# ESP32-H2 register map
Vendor: ESPRESSIF SYSTEMS (SHANGHAI) CO., LTD.; Series: ESP32 H-Series; File version: 12
CPU: RV32IMAC r0p0, little endian, no MPU, no FPU, 0 interrupt priority bits
Address unit: 32 bits
Registers are 32-bit, read-write, reset 0x0 unless marked. A register's access mark holds for its fields unless they carry their own. Offsets are from the block's base; [hi:lo] are bit positions; {n}, {i} and the like mark numbered series.

## MCPWM0 — Motor Control Pulse-Width Modulation 0
Base 0x60014000
0x00 CLK_CFG — PWM clock prescaler register.
  [7:0] CLK_PRESCALE — Period of PWM_clk = 6.25ns * (PWM_CLK_PRESCALE + 1)
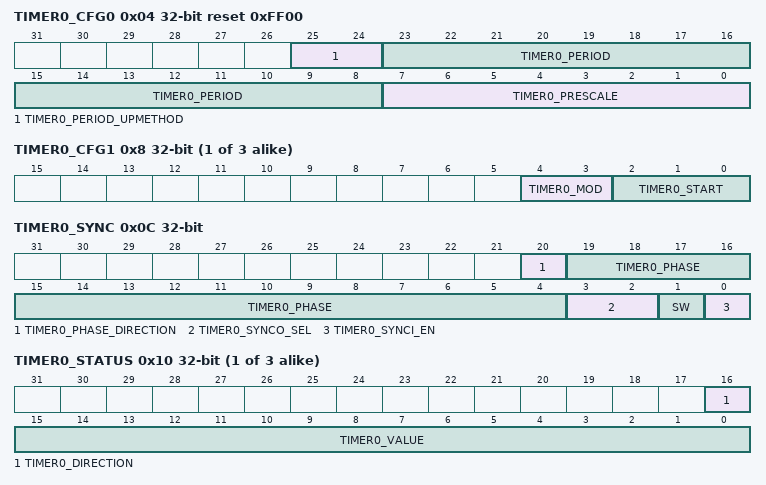
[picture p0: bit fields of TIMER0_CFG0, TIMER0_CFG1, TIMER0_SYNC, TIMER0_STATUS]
0x04 TIMER0_CFG0 reset 0xFF00 — PWM timer0 period and update method configuration register.
  [25:24] TIMER0_PERIOD_UPMETHOD — Update method for active register of PWM timer0 period, 0: immediate, 1: TEZ, 2: sync, 3: TEZ | sync. TEZ here and below means timer equal zero event
  [23:8] TIMER0_PERIOD — period shadow register of PWM timer0
  [7:0] TIMER0_PRESCALE — period of PT0_clk = Period of PWM_clk * (PWM_TIMER0_PRESCALE + 1)
{0x8+0x10*i} TIMER{i}_CFG1 (i=0..2) — PWM timer{i} working mode and start/stop control configuration register.
  [4:3] TIMER{i}_MOD — PWM timer{i} working mode, 0: freeze, 1: increase mode, 2: decrease mode, 3: up-down mode
  [2:0] TIMER{i}_START — PWM timer{i} start and stop control. 0: if PWM timer{i} starts, then stops at TEZ, 1: if timer{i} starts, then stops at TEP, 2: PWM timer{i} starts and runs on, 3: timer{i} starts and stops at the next TEZ, 4: timer{i} starts and stops at the next TEP. TEP here and below means the event that happens when the timer equals to period
0x0C TIMER0_SYNC — PWM timer0 sync function configuration register.
  [20] TIMER0_PHASE_DIRECTION — Configure the PWM timer0's direction when timer0 mode is up-down mode: 0-increase,1-decrease
  [19:4] TIMER0_PHASE — phase for timer reload on sync event
  [3:2] TIMER0_SYNCO_SEL — PWM timer0 sync_out selection, 0: sync_in, 1: TEZ, 2: TEP, and sync out will always generate when toggling the reg_timer0_sync_sw bit
  [1] SW — Toggling this bit will trigger a software sync.
  [0] TIMER0_SYNCI_EN — When set, timer reloading with phase on sync input event is enabled.
{0x10+0x10*i} TIMER{i}_STATUS ro (i=0..2) — PWM timer{i} status register.
  [16] TIMER{i}_DIRECTION — current PWM timer{i} counter direction, 0: increment 1: decrement
  [15:0] TIMER{i}_VALUE — current PWM timer{i} counter value
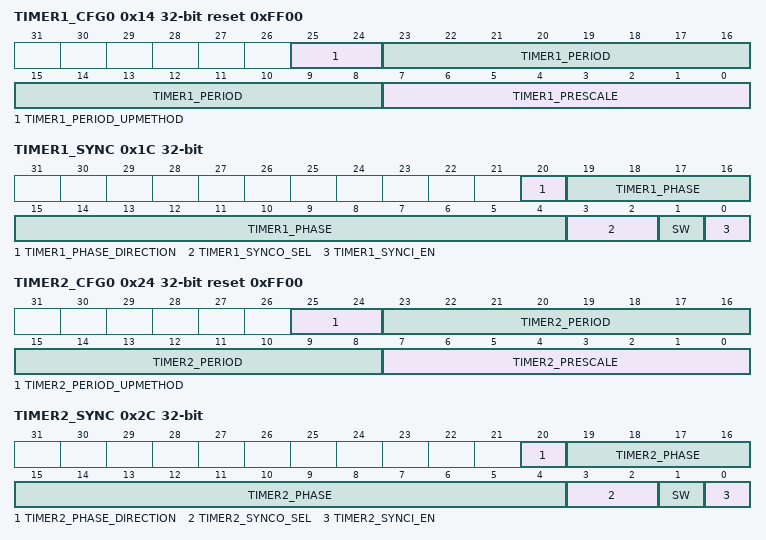
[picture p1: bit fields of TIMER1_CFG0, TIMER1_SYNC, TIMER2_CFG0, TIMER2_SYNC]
0x14 TIMER1_CFG0 reset 0xFF00 — PWM timer1 period and update method configuration register.
  [25:24] TIMER1_PERIOD_UPMETHOD — Update method for active register of PWM timer1 period, 0: immediate, 1: TEZ, 2: sync, 3: TEZ | sync. TEZ here and below means timer equal zero event
  [23:8] TIMER1_PERIOD — period shadow register of PWM timer1
  [7:0] TIMER1_PRESCALE — period of PT0_clk = Period of PWM_clk * (PWM_timer1_PRESCALE + 1)
0x1C TIMER1_SYNC — PWM timer1 sync function configuration register.
  [20] TIMER1_PHASE_DIRECTION — Configure the PWM timer1's direction when timer1 mode is up-down mode: 0-increase,1-decrease
  [19:4] TIMER1_PHASE — phase for timer reload on sync event
  [3:2] TIMER1_SYNCO_SEL — PWM timer1 sync_out selection, 0: sync_in, 1: TEZ, 2: TEP, and sync out will always generate when toggling the reg_timer1_sync_sw bit
  [1] SW — Toggling this bit will trigger a software sync.
  [0] TIMER1_SYNCI_EN — When set, timer reloading with phase on sync input event is enabled.
0x24 TIMER2_CFG0 reset 0xFF00 — PWM timer2 period and update method configuration register.
  [25:24] TIMER2_PERIOD_UPMETHOD — Update method for active register of PWM timer2 period, 0: immediate, 1: TEZ, 2: sync, 3: TEZ | sync. TEZ here and below means timer equal zero event
  [23:8] TIMER2_PERIOD — period shadow register of PWM timer2
  [7:0] TIMER2_PRESCALE — period of PT0_clk = Period of PWM_clk * (PWM_timer2_PRESCALE + 1)
0x2C TIMER2_SYNC — PWM timer2 sync function configuration register.
  [20] TIMER2_PHASE_DIRECTION — Configure the PWM timer2's direction when timer2 mode is up-down mode: 0-increase,1-decrease
  [19:4] TIMER2_PHASE — phase for timer reload on sync event
  [3:2] TIMER2_SYNCO_SEL — PWM timer2 sync_out selection, 0: sync_in, 1: TEZ, 2: TEP, and sync out will always generate when toggling the reg_timer0_sync_sw bit
  [1] SW — Toggling this bit will trigger a software sync.
  [0] TIMER2_SYNCI_EN — When set, timer reloading with phase on sync input event is enabled.
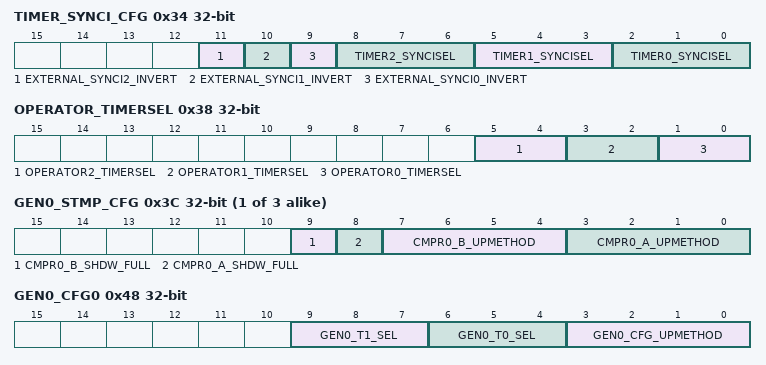
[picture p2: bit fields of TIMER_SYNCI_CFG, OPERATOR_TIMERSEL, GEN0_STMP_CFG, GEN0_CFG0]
0x34 TIMER_SYNCI_CFG — Synchronization input selection for three PWM timers.
  [11] EXTERNAL_SYNCI2_INVERT — invert SYNC2 from GPIO matrix
  [10] EXTERNAL_SYNCI1_INVERT — invert SYNC1 from GPIO matrix
  [9] EXTERNAL_SYNCI0_INVERT — invert SYNC0 from GPIO matrix
  [8:6] TIMER2_SYNCISEL — select sync input for PWM timer2, 1: PWM timer0 sync_out, 2: PWM timer1 sync_out, 3: PWM timer2 sync_out, 4: SYNC0 from GPIO matrix, 5: SYNC1 from GPIO matrix, 6: SYNC2 from GPIO matrix, other values: no sync input selected
  [5:3] TIMER1_SYNCISEL — select sync input for PWM timer1, 1: PWM timer0 sync_out, 2: PWM timer1 sync_out, 3: PWM timer2 sync_out, 4: SYNC0 from GPIO matrix, 5: SYNC1 from GPIO matrix, 6: SYNC2 from GPIO matrix, other values: no sync input selected
  [2:0] TIMER0_SYNCISEL — select sync input for PWM timer0, 1: PWM timer0 sync_out, 2: PWM timer1 sync_out, 3: PWM timer2 sync_out, 4: SYNC0 from GPIO matrix, 5: SYNC1 from GPIO matrix, 6: SYNC2 from GPIO matrix, other values: no sync input selected
0x38 OPERATOR_TIMERSEL — Select specific timer for PWM operators.
  [5:4] OPERATOR2_TIMERSEL — Select which PWM timer's is the timing reference for PWM operator2, 0: timer0, 1: timer1, 2: timer2
  [3:2] OPERATOR1_TIMERSEL — Select which PWM timer's is the timing reference for PWM operator1, 0: timer0, 1: timer1, 2: timer2
  [1:0] OPERATOR0_TIMERSEL — Select which PWM timer's is the timing reference for PWM operator0, 0: timer0, 1: timer1, 2: timer2
{0x3C+0x38*i} GEN{i}_STMP_CFG (i=0..2) — Transfer status and update method for time stamp registers A and B
  [9] CMPR{i}_B_SHDW_FULL — Set and reset by hardware. If set, PWM generator {i} time stamp B's shadow reg is filled and waiting to be transferred to B's active reg. If cleared, B's active reg has been updated with shadow register latest value
  [8] CMPR{i}_A_SHDW_FULL — Set and reset by hardware. If set, PWM generator {i} time stamp A's shadow reg is filled and waiting to be transferred to A's active reg. If cleared, A's active reg has been updated with shadow register latest value
  [7:4] CMPR{i}_B_UPMETHOD — Update method for PWM generator {i} time stamp B's active register. When all bits are set to 0: immediately, when bit0 is set to 1: TEZ, when bit1 is set to 1: TEP,when bit2 is set to 1: sync, when bit3 is set to 1: disable the update.
  [3:0] CMPR{i}_A_UPMETHOD — Update method for PWM generator {i} time stamp A's active register. When all bits are set to 0: immediately, when bit0 is set to 1: TEZ, when bit1 is set to 1: TEP,when bit2 is set to 1: sync, when bit3 is set to 1: disable the update.
{0x40+0x38*i} GEN{i}_TSTMP_A (i=0..2) — Shadow register for register A.
  [15:0] CMPR{i}_A — PWM generator {i} time stamp A's shadow register
{0x44+0x38*i} GEN{i}_TSTMP_B (i=0..2) — Shadow register for register B.
  [15:0] CMPR{i}_B — PWM generator {i} time stamp B's shadow register
0x48 GEN0_CFG0 — Fault event T0 and T1 handling
  [9:7] GEN0_T1_SEL — Source selection for PWM generator 0 event_t1, take effect immediately, 0: fault_event0, 1: fault_event1, 2: fault_event2, 3: sync_taken, 4: none
  [6:4] GEN0_T0_SEL — Source selection for PWM generator 0 event_t0, take effect immediately, 0: fault_event0, 1: fault_event1, 2: fault_event2, 3: sync_taken, 4: none
  [3:0] GEN0_CFG_UPMETHOD — Update method for PWM generator 0's active register of configuration. When all bits are set to 0: immediately, when bit0 is set to 1: TEZ, when bit1 is set to 1:TEP,when bit2 is set to 1:sync,when bit3 is set to 1:disable the update
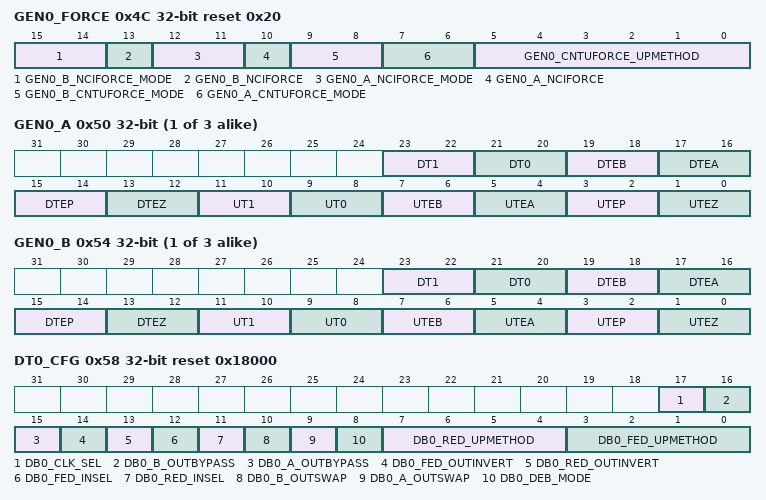
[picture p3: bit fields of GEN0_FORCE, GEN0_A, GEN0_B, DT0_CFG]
0x4C GEN0_FORCE reset 0x20 — Permissives to force PWM0A and PWM0B outputs by software
  [15:14] GEN0_B_NCIFORCE_MODE — non-continuous immediate software force mode for PWM0B, 0: disabled, 1: low, 2: high, 3: disabled
  [13] GEN0_B_NCIFORCE — Trigger of non-continuous immediate software-force event for PWM0B, a toggle will trigger a force event.
  [12:11] GEN0_A_NCIFORCE_MODE — non-continuous immediate software force mode for PWM0A, 0: disabled, 1: low, 2: high, 3: disabled
  [10] GEN0_A_NCIFORCE — Trigger of non-continuous immediate software-force event for PWM0A, a toggle will trigger a force event.
  [9:8] GEN0_B_CNTUFORCE_MODE — Continuous software force mode for PWM0B. 0: disabled, 1: low, 2: high, 3: disabled
  [7:6] GEN0_A_CNTUFORCE_MODE — Continuous software force mode for PWM0A. 0: disabled, 1: low, 2: high, 3: disabled
  [5:0] GEN0_CNTUFORCE_UPMETHOD — Updating method for continuous software force of PWM generator0. When all bits are set to 0: immediately, when bit0 is set to 1: TEZ,,when bit1 is set to 1: TEP, when bit2 is set to 1: TEA, when bit3 is set to 1: TEB, when bit4 is set to 1: sync, when bit5 is set to 1: disable update. (TEA/B here and below means an event generated when the timer's value equals to that of register A/B.)
{0x50+0x38*i} GEN{i}_A (i=0..2) — Actions triggered by events on PWM{i}A
  [23:22] DT1 — Action on PWM{i}A triggered by event_t1 when timer decreasing. 0: no change, 1: low, 2: high, 3: toggle
  [21:20] DT0 — Action on PWM{i}A triggered by event_t0 when timer decreasing
  [19:18] DTEB — Action on PWM{i}A triggered by event TEB when timer decreasing
  [17:16] DTEA — Action on PWM{i}A triggered by event TEA when timer decreasing
  [15:14] DTEP — Action on PWM{i}A triggered by event TEP when timer decreasing
  [13:12] DTEZ — Action on PWM{i}A triggered by event TEZ when timer decreasing
  [11:10] UT1 — Action on PWM{i}A triggered by event_t1 when timer increasing
  [9:8] UT0 — Action on PWM{i}A triggered by event_t0 when timer increasing
  [7:6] UTEB — Action on PWM{i}A triggered by event TEB when timer increasing
  [5:4] UTEA — Action on PWM{i}A triggered by event TEA when timer increasing
  [3:2] UTEP — Action on PWM{i}A triggered by event TEP when timer increasing
  [1:0] UTEZ — Action on PWM{i}A triggered by event TEZ when timer increasing
{0x54+0x38*i} GEN{i}_B (i=0..2) — Actions triggered by events on PWM{i}B
  [23:22] DT1 — Action on PWM{i}B triggered by event_t1 when timer decreasing. 0: no change, 1: low, 2: high, 3: toggle
  [21:20] DT0 — Action on PWM{i}B triggered by event_t0 when timer decreasing
  [19:18] DTEB — Action on PWM{i}B triggered by event TEB when timer decreasing
  [17:16] DTEA — Action on PWM{i}B triggered by event TEA when timer decreasing
  [15:14] DTEP — Action on PWM{i}B triggered by event TEP when timer decreasing
  [13:12] DTEZ — Action on PWM{i}B triggered by event TEZ when timer decreasing
  [11:10] UT1 — Action on PWM{i}B triggered by event_t1 when timer increasing
  [9:8] UT0 — Action on PWM{i}B triggered by event_t0 when timer increasing
  [7:6] UTEB — Action on PWM{i}B triggered by event TEB when timer increasing
  [5:4] UTEA — Action on PWM{i}B triggered by event TEA when timer increasing
  [3:2] UTEP — Action on PWM{i}B triggered by event TEP when timer increasing
  [1:0] UTEZ — Action on PWM{i}B triggered by event TEZ when timer increasing
0x58 DT0_CFG reset 0x18000 — dead time type selection and configuration
  [17] DB0_CLK_SEL — Dead time generator 0 clock selection. 0: PWM_clk, 1: PT_clk
  [16] DB0_B_OUTBYPASS — S0 in table
  [15] DB0_A_OUTBYPASS — S1 in table
  [14] DB0_FED_OUTINVERT — S3 in table
  [13] DB0_RED_OUTINVERT — S2 in table
  [12] DB0_FED_INSEL — S5 in table
  [11] DB0_RED_INSEL — S4 in table
  [10] DB0_B_OUTSWAP — S7 in table
  [9] DB0_A_OUTSWAP — S6 in table
  [8] DB0_DEB_MODE — S8 in table, dual-edge B mode, 0: fed/red take effect on different path separately, 1: fed/red take effect on B path, A out is in bypass or dulpB mode
  [7:4] DB0_RED_UPMETHOD — Update method for RED (rising edge delay) active register. 0: immediate, when bit0 is set to 1: tez, when bit1 is set to 1:tep, when bit2 is set to 1: sync, when bit3 is set to 1: disable the update
  [3:0] DB0_FED_UPMETHOD — Update method for FED (rising edge delay) active register. 0: immediate, when bit0 is set to 1: tez, when bit1 is set to 1:tep, when bit2 is set to 1: sync, when bit3 is set to 1: disable the update
{0x5C+0x38*i} DT{i}_FED_CFG (i=0..2) — Shadow register for falling edge delay (FED).
  [15:0] DB{i}_FED — Shadow register for FED
{0x60+0x38*i} DT{i}_RED_CFG (i=0..2) — Shadow register for rising edge delay (RED).
  [15:0] DB{i}_RED — Shadow register for RED
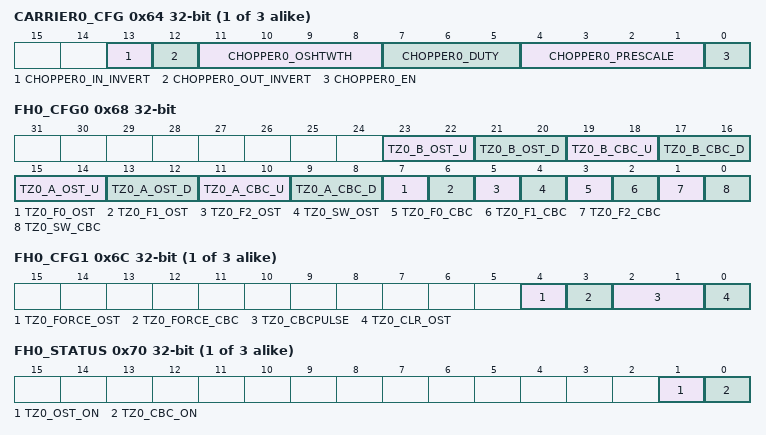
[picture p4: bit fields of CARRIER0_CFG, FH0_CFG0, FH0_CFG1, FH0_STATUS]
{0x64+0x38*i} CARRIER{i}_CFG (i=0..2) — Carrier enable and configuratoin
  [13] CHOPPER{i}_IN_INVERT — when set, invert the input of PWM{i}A and PWM{i}B for this submodule
  [12] CHOPPER{i}_OUT_INVERT — when set, invert the output of PWM{i}A and PWM{i}B for this submodule
  [11:8] CHOPPER{i}_OSHTWTH — width of the first pulse in number of periods of the carrier
  [7:5] CHOPPER{i}_DUTY — carrier duty selection. Duty = PWM_CARRIER0_DUTY / 8
  [4:1] CHOPPER{i}_PRESCALE — PWM carrier{i} clock (PC_clk) prescale value. Period of PC_clk = period of PWM_clk * (PWM_CARRIER0_PRESCALE + 1)
  [0] CHOPPER{i}_EN — When set, carrier{i} function is enabled. When cleared, carrier{i} is bypassed
0x68 FH0_CFG0 — Actions on PWM0A and PWM0B trip events
  [23:22] TZ0_B_OST_U — One-shot mode action on PWM0B when fault event occurs and timer is increasing. 0: do nothing, 1: force low, 2: force high, 3: toggle
  [21:20] TZ0_B_OST_D — One-shot mode action on PWM0B when fault event occurs and timer is decreasing. 0: do nothing, 1: force low, 2: force high, 3: toggle
  [19:18] TZ0_B_CBC_U — Cycle-by-cycle mode action on PWM0B when fault event occurs and timer is increasing. 0: do nothing,1: force low, 2: force high, 3: toggle
  [17:16] TZ0_B_CBC_D — Cycle-by-cycle mode action on PWM0B when fault event occurs and timer is decreasing. 0: do nothing, 1: force low, 2: force high, 3: toggle
  [15:14] TZ0_A_OST_U — One-shot mode action on PWM0A when fault event occurs and timer is increasing. 0: do nothing, 1: force low, 2: force high, 3: toggle
  [13:12] TZ0_A_OST_D — One-shot mode action on PWM0A when fault event occurs and timer is decreasing. 0: do nothing, 1: force low, 2: force high, 3: toggle
  [11:10] TZ0_A_CBC_U — Cycle-by-cycle mode action on PWM0A when fault event occurs and timer is increasing. 0: do nothing, 1: force low, 2: force high, 3: toggle
  [9:8] TZ0_A_CBC_D — Cycle-by-cycle mode action on PWM0A when fault event occurs and timer is decreasing. 0: do nothing, 1: force low, 2: force high, 3: toggle
  [7] TZ0_F0_OST — event_f0 will trigger one-shot mode action. 0: disable, 1: enable
  [6] TZ0_F1_OST — event_f1 will trigger one-shot mode action. 0: disable, 1: enable
  [5] TZ0_F2_OST — event_f2 will trigger one-shot mode action. 0: disable, 1: enable
  [4] TZ0_SW_OST — Enable register for software force one-shot mode action. 0: disable, 1: enable
  [3] TZ0_F0_CBC — event_f0 will trigger cycle-by-cycle mode action. 0: disable, 1: enable
  [2] TZ0_F1_CBC — event_f1 will trigger cycle-by-cycle mode action. 0: disable, 1: enable
  [1] TZ0_F2_CBC — event_f2 will trigger cycle-by-cycle mode action. 0: disable, 1: enable
  [0] TZ0_SW_CBC — Enable register for software force cycle-by-cycle mode action. 0: disable, 1: enable
{0x6C+0x38*i} FH{i}_CFG1 (i=0..2) — Software triggers for fault handler actions
  [4] TZ{i}_FORCE_OST — a toggle (software negate its value) triggers a one-shot mode action
  [3] TZ{i}_FORCE_CBC — a toggle trigger a cycle-by-cycle mode action
  [2:1] TZ{i}_CBCPULSE — cycle-by-cycle mode action refresh moment selection. When bit0 is set to 1: TEZ, when bit1 is set to 1:TEP
  [0] TZ{i}_CLR_OST — a rising edge will clear on going one-shot mode action
{0x70+0x38*i} FH{i}_STATUS ro (i=0..2) — Status of fault events.
  [1] TZ{i}_OST_ON — Set and reset by hardware. If set, an one-shot mode action is on going
  [0] TZ{i}_CBC_ON — Set and reset by hardware. If set, a cycle-by-cycle mode action is on going
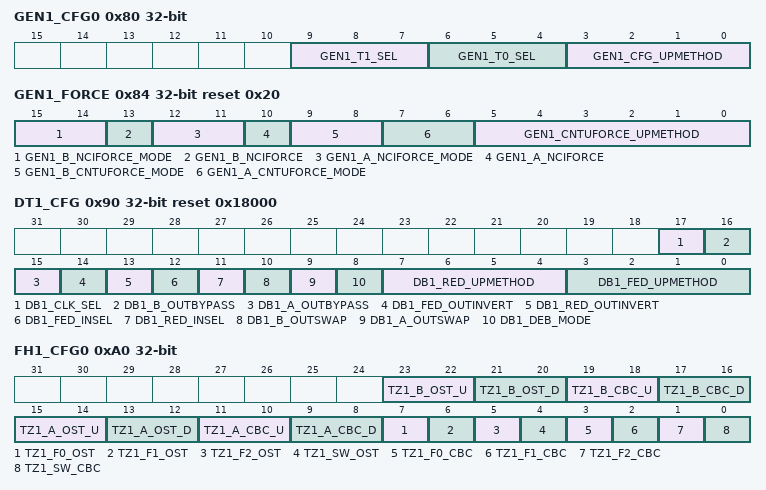
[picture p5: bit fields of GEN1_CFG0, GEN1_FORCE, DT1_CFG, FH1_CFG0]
0x80 GEN1_CFG0 — Fault event T0 and T1 handling
  [9:7] GEN1_T1_SEL — Source selection for PWM generator 1 event_t1, take effect immediately, 0: fault_event0, 1: fault_event1, 2: fault_event2, 3: sync_taken, 4: none
  [6:4] GEN1_T0_SEL — Source selection for PWM generator 1 event_t0, take effect immediately, 0: fault_event0, 1: fault_event1, 2: fault_event2, 3: sync_taken, 4: none
  [3:0] GEN1_CFG_UPMETHOD — Update method for PWM generator 1's active register of configuration. When all bits are set to 0: immediately, when bit0 is set to 1: TEZ, when bit1 is set to 1:sync;when bit3 is set to 1:disable the update.
0x84 GEN1_FORCE reset 0x20 — Permissives to force PWM1A and PWM1B outputs by software
  [15:14] GEN1_B_NCIFORCE_MODE — non-continuous immediate software force mode for PWM1B, 0: disabled, 1: low, 2: high, 3: disabled
  [13] GEN1_B_NCIFORCE — Trigger of non-continuous immediate software-force event for PWM1B, a toggle will trigger a force event.
  [12:11] GEN1_A_NCIFORCE_MODE — non-continuous immediate software force mode for PWM1A, 0: disabled, 1: low, 2: high, 3: disabled
  [10] GEN1_A_NCIFORCE — Trigger of non-continuous immediate software-force event for PWM1A, a toggle will trigger a force event.
  [9:8] GEN1_B_CNTUFORCE_MODE — Continuous software force mode for PWM1B. 0: disabled, 1: low, 2: high, 3: disabled
  [7:6] GEN1_A_CNTUFORCE_MODE — Continuous software force mode for PWM1A. 0: disabled, 1: low, 2: high, 3: disabled
  [5:0] GEN1_CNTUFORCE_UPMETHOD — Updating method for continuous software force of PWM generator 1. When all bits are set to 0: immediately, when bit0 is set to 1: TEZ,,when bit1 is set to 1: TEP, when bit2 is set to 1: TEA, when bit3 is set to 1: TEB, when bit4 is set to 1: sync, when bit5 is set to 1: disable update. (TEA/B here and below means an event generated when the timer's value equals to that of register A/B.)
0x90 DT1_CFG reset 0x18000 — dead time type selection and configuration
  [17] DB1_CLK_SEL — Dead time generator 1 clock selection. 0: PWM_clk, 1: PT_clk
  [16] DB1_B_OUTBYPASS — S0 in table
  [15] DB1_A_OUTBYPASS — S1 in table
  [14] DB1_FED_OUTINVERT — S3 in table
  [13] DB1_RED_OUTINVERT — S2 in table
  [12] DB1_FED_INSEL — S5 in table
  [11] DB1_RED_INSEL — S4 in table
  [10] DB1_B_OUTSWAP — S7 in table
  [9] DB1_A_OUTSWAP — S6 in table
  [8] DB1_DEB_MODE — S8 in table, dual-edge B mode, 0: fed/red take effect on different path separately, 1: fed/red take effect on B path, A out is in bypass or dulpB mode
  [7:4] DB1_RED_UPMETHOD — Update method for RED (rising edge delay) active register. 0: immediate,when bit0 is set to 1: tez, when bit1 is set to 1:tep, when bit2 is set to 1: sync, when bit3 is set to 1: disable the update
  [3:0] DB1_FED_UPMETHOD — Update method for FED (falling edge delay) active register. 0: immediate, when bit0 is set to 1: tez, when bit1 is set to 1:tep, when bit2 is set to 1: sync, when bit3 is set to 1: disable the update
0xA0 FH1_CFG0 — Actions on PWM1A and PWM1B trip events
  [23:22] TZ1_B_OST_U — One-shot mode action on PWM1B when fault event occurs and timer is increasing. 0: do nothing, 1: force low, 2: force high, 3: toggle
  [21:20] TZ1_B_OST_D — One-shot mode action on PWM1B when fault event occurs and timer is decreasing. 0: do nothing, 1: force low, 2: force high, 3: toggle
  [19:18] TZ1_B_CBC_U — Cycle-by-cycle mode action on PWM1B when fault event occurs and timer is increasing. 0: do nothing, 1: force low, 2: force high, 3: toggle
  [17:16] TZ1_B_CBC_D — Cycle-by-cycle mode action on PWM1B when fault event occurs and timer is decreasing. 0: do nothing, 1: force low, 2: force high, 3: toggle
  [15:14] TZ1_A_OST_U — One-shot mode action on PWM1A when fault event occurs and timer is increasing. 0: do nothing, 1: force low, 2: force high, 3: toggle
  [13:12] TZ1_A_OST_D — One-shot mode action on PWM1A when fault event occurs and timer is decreasing. 0: do nothing,1: force low, 2: force high, 3: toggle
  [11:10] TZ1_A_CBC_U — Cycle-by-cycle mode action on PWM1A when fault event occurs and timer is increasing. 0: do nothing, 1: force low, 2: force high, 3: toggle
  [9:8] TZ1_A_CBC_D — Cycle-by-cycle mode action on PWM1A when fault event occurs and timer is decreasing. 0: do nothing, 1: force low, 2: force high, 3: toggle
  [7] TZ1_F0_OST — event_f0 will trigger one-shot mode action. 0: disable, 1: enable
  [6] TZ1_F1_OST — event_f1 will trigger one-shot mode action. 0: disable, 1: enable
  [5] TZ1_F2_OST — event_f2 will trigger one-shot mode action. 0: disable, 1: enable
  [4] TZ1_SW_OST — Enable register for software force one-shot mode action. 0: disable, 1: enable
  [3] TZ1_F0_CBC — event_f0 will trigger cycle-by-cycle mode action. 0: disable, 1: enable
  [2] TZ1_F1_CBC — event_f1 will trigger cycle-by-cycle mode action. 0: disable, 1: enable
  [1] TZ1_F2_CBC — event_f2 will trigger cycle-by-cycle mode action. 0: disable, 1: enable
  [0] TZ1_SW_CBC — Enable register for software force cycle-by-cycle mode action. 0: disable, 1: enable
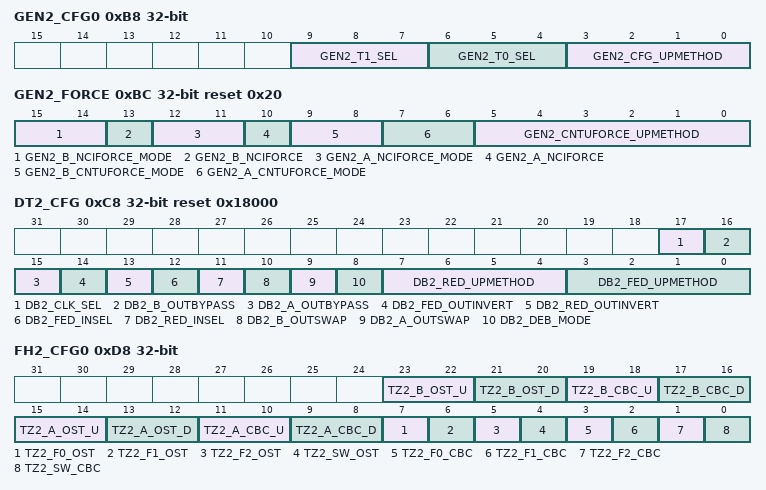
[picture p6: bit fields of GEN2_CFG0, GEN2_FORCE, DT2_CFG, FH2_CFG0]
0xB8 GEN2_CFG0 — Fault event T0 and T1 handling
  [9:7] GEN2_T1_SEL — Source selection for PWM generator 2 event_t1, take effect immediately, 0: fault_event0, 1: fault_event1, 2: fault_event2, 3: sync_taken, 4: none
  [6:4] GEN2_T0_SEL — Source selection for PWM generator 2 event_t0, take effect immediately, 0: fault_event0, 1: fault_event1, 2: fault_event2, 3: sync_taken, 4: none
  [3:0] GEN2_CFG_UPMETHOD — Update method for PWM generator 2's active register of configuration. 0: immediately, when bit0 is set to 1: TEZ, when bit1 is set to 1:sync;when bit3 is set to 1:disable the update.
0xBC GEN2_FORCE reset 0x20 — Permissives to force PWM2A and PWM2B outputs by software
  [15:14] GEN2_B_NCIFORCE_MODE — non-continuous immediate software force mode for PWM2B, 0: disabled, 1: low, 2: high, 3: disabled
  [13] GEN2_B_NCIFORCE — Trigger of non-continuous immediate software-force event for PWM2B, a toggle will trigger a force event.
  [12:11] GEN2_A_NCIFORCE_MODE — non-continuous immediate software force mode for PWM2A, 0: disabled, 1: low, 2: high, 3: disabled
  [10] GEN2_A_NCIFORCE — Trigger of non-continuous immediate software-force event for PWM2A, a toggle will trigger a force event.
  [9:8] GEN2_B_CNTUFORCE_MODE — Continuous software force mode for PWM2B. 0: disabled, 1: low, 2: high, 3: disabled
  [7:6] GEN2_A_CNTUFORCE_MODE — Continuous software force mode for PWM2A. 0: disabled, 1: low, 2: high, 3: disabled
  [5:0] GEN2_CNTUFORCE_UPMETHOD — Updating method for continuous software force of PWM generator 2. When all bits are set to 0: immediately, when bit0 is set to 1: TEZ,when bit1 is set to 1: TEP, when bit2 is set to 1: TEA, when bit3 is set to 1: TEB, when bit4 is set to 1: sync, when bit5 is set to 1: disable update. (TEA/B here and below means an event generated when the timer's value equals to that of register A/B.)
0xC8 DT2_CFG reset 0x18000 — dead time type selection and configuration
  [17] DB2_CLK_SEL — Dead time generator 2 clock selection. 0: PWM_clk, 1: PT_clk
  [16] DB2_B_OUTBYPASS — S0 in table
  [15] DB2_A_OUTBYPASS — S1 in table
  [14] DB2_FED_OUTINVERT — S3 in table
  [13] DB2_RED_OUTINVERT — S2 in table
  [12] DB2_FED_INSEL — S5 in table
  [11] DB2_RED_INSEL — S4 in table
  [10] DB2_B_OUTSWAP — S7 in table
  [9] DB2_A_OUTSWAP — S6 in table
  [8] DB2_DEB_MODE — S8 in table, dual-edge B mode, 0: fed/red take effect on different path separately, 1: fed/red take effect on B path, A out is in bypass or dulpB mode
  [7:4] DB2_RED_UPMETHOD — Update method for RED (rising edge delay) active register. 0: immediate,when bit0 is set to 1: tez, when bit1 is set to 1:tep, when bit2 is set to 1: sync, when bit3 is set to 1: disable the update
  [3:0] DB2_FED_UPMETHOD — Update method for FED (falling edge delay) active register. 0: immediate,when bit0 is set to 1: tez, when bit1 is set to 1:tep, when bit2 is set to 1: sync, when bit3 is set to 1: disable the update
0xD8 FH2_CFG0 — Actions on PWM2A and PWM2B trip events
  [23:22] TZ2_B_OST_U — One-shot mode action on PWM2B when fault event occurs and timer is increasing. 0: do nothing, 1: force low, 2: force high, 3: toggle
  [21:20] TZ2_B_OST_D — One-shot mode action on PWM2B when fault event occurs and timer is decreasing. 0: do nothing, 1: force low, 2: force high, 3: toggle
  [19:18] TZ2_B_CBC_U — Cycle-by-cycle mode action on PWM2B when fault event occurs and timer is increasing. 0: do nothing, 1: force low, 2: force high, 3: toggle
  [17:16] TZ2_B_CBC_D — Cycle-by-cycle mode action on PWM2B when fault event occurs and timer is decreasing. 0: do nothing, 1: force low, 2: force high, 3: toggle
  [15:14] TZ2_A_OST_U — One-shot mode action on PWM2A when fault event occurs and timer is increasing. 0: do nothing, 1: force low, 2: force high, 3: toggle
  [13:12] TZ2_A_OST_D — One-shot mode action on PWM2A when fault event occurs and timer is decreasing. 0: do nothing, 1: force low, 2: force high, 3: toggle
  [11:10] TZ2_A_CBC_U — Cycle-by-cycle mode action on PWM2A when fault event occurs and timer is increasing. 0: do nothing, 1: force low, 2: force high, 3: toggle
  [9:8] TZ2_A_CBC_D — Cycle-by-cycle mode action on PWM2A when fault event occurs and timer is decreasing. 0: do nothing, 1: force low, 2: force high, 3: toggle
  [7] TZ2_F0_OST — event_f0 will trigger one-shot mode action. 0: disable, 1: enable
  [6] TZ2_F1_OST — event_f1 will trigger one-shot mode action. 0: disable, 1: enable
  [5] TZ2_F2_OST — event_f2 will trigger one-shot mode action. 0: disable, 1: enable
  [4] TZ2_SW_OST — Enable register for software force one-shot mode action. 0: disable, 1: enable
  [3] TZ2_F0_CBC — event_f0 will trigger cycle-by-cycle mode action. 0: disable, 1: enable
  [2] TZ2_F1_CBC — event_f1 will trigger cycle-by-cycle mode action. 0: disable, 1: enable
  [1] TZ2_F2_CBC — event_f2 will trigger cycle-by-cycle mode action. 0: disable, 1: enable
  [0] TZ2_SW_CBC — Enable register for software force cycle-by-cycle mode action. 0: disable, 1: enable
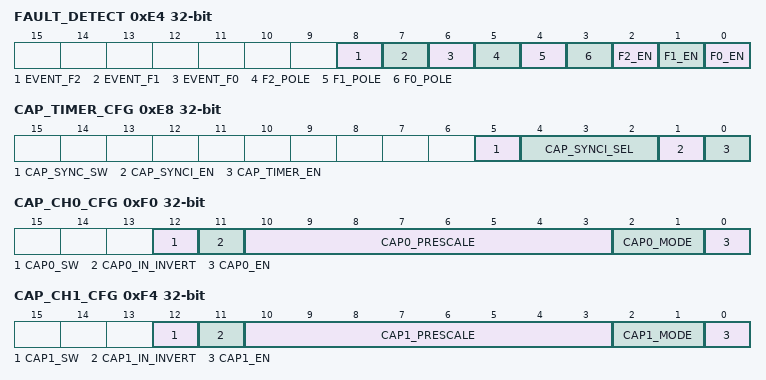
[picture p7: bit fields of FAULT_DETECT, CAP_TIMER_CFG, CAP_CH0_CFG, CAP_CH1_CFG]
0xE4 FAULT_DETECT access per field — Fault detection configuration and status
  [8] EVENT_F2 ro — Set and reset by hardware. If set, event_f2 is on going
  [7] EVENT_F1 ro — Set and reset by hardware. If set, event_f1 is on going
  [6] EVENT_F0 ro — Set and reset by hardware. If set, event_f0 is on going
  [5] F2_POLE rw — Set event_f2 trigger polarity on FAULT2 source from GPIO matrix. 0: level low, 1: level high
  [4] F1_POLE rw — Set event_f1 trigger polarity on FAULT2 source from GPIO matrix. 0: level low, 1: level high
  [3] F0_POLE rw — Set event_f0 trigger polarity on FAULT2 source from GPIO matrix. 0: level low, 1: level high
  [2] F2_EN rw — When set, event_f2 generation is enabled
  [1] F1_EN rw — When set, event_f1 generation is enabled
  [0] F0_EN rw — When set, event_f0 generation is enabled
0xE8 CAP_TIMER_CFG access per field — Configure capture timer
  [5] CAP_SYNC_SW wo — When reg_cap_synci_en is 1, write 1 will trigger a capture timer sync, capture timer is loaded with value in phase register.
  [4:2] CAP_SYNCI_SEL rw — capture module sync input selection. 0: none, 1: timer0 sync_out, 2: timer1 sync_out, 3: timer2 sync_out, 4: SYNC0 from GPIO matrix, 5: SYNC1 from GPIO matrix, 6: SYNC2 from GPIO matrix
  [1] CAP_SYNCI_EN rw — When set, capture timer sync is enabled.
  [0] CAP_TIMER_EN rw — When set, capture timer incrementing under APB_clk is enabled.
0xEC CAP_TIMER_PHASE — Phase for capture timer sync
  [31:0] CAP_PHASE — Phase value for capture timer sync operation.
0xF0 CAP_CH0_CFG access per field — Capture channel 0 configuration and enable
  [12] CAP0_SW wo — Write 1 will trigger a software forced capture on channel 0
  [11] CAP0_IN_INVERT rw — when set, CAP0 form GPIO matrix is inverted before prescale
  [10:3] CAP0_PRESCALE rw — Value of prescaling on possitive edge of CAP0. Prescale value = PWM_CAP0_PRESCALE + 1
  [2:1] CAP0_MODE rw — Edge of capture on channel 0 after prescaling. When bit0 is set to 1: enable capture on the negative edge, When bit1 is set to 1: enable capture on the positive edge.
  [0] CAP0_EN rw — When set, capture on channel 0 is enabled
0xF4 CAP_CH1_CFG access per field — Capture channel 1 configuration and enable
  [12] CAP1_SW wo — Write 1 will trigger a software forced capture on channel 1
  [11] CAP1_IN_INVERT rw — when set, CAP1 form GPIO matrix is inverted before prescale
  [10:3] CAP1_PRESCALE rw — Value of prescaling on possitive edge of CAP1. Prescale value = PWM_CAP1_PRESCALE + 1
  [2:1] CAP1_MODE rw — Edge of capture on channel 1 after prescaling. When bit0 is set to 1: enable capture on the negative edge, When bit1 is set to 1: enable capture on the positive edge.
  [0] CAP1_EN rw — When set, capture on channel 2 is enabled
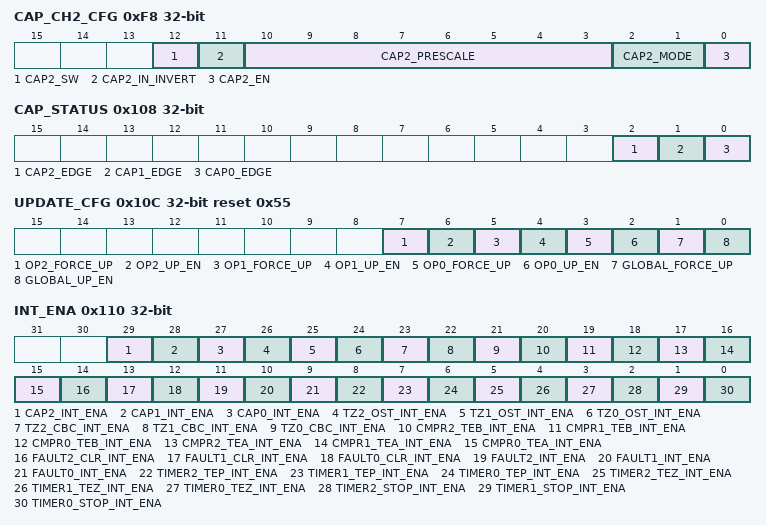
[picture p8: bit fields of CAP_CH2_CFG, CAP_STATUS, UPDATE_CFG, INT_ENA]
0xF8 CAP_CH2_CFG access per field — Capture channel 2 configuration and enable
  [12] CAP2_SW wo — Write 1 will trigger a software forced capture on channel 2
  [11] CAP2_IN_INVERT rw — when set, CAP2 form GPIO matrix is inverted before prescale
  [10:3] CAP2_PRESCALE rw — Value of prescaling on possitive edge of CAP2. Prescale value = PWM_CAP2_PRESCALE + 1
  [2:1] CAP2_MODE rw — Edge of capture on channel 2 after prescaling. When bit0 is set to 1: enable capture on the negative edge, When bit1 is set to 1: enable capture on the positive edge.
  [0] CAP2_EN rw — When set, capture on channel 2 is enabled
{0xFC+4i} CAP_CH{i} ro (i=0..2) — ch{i} capture value status register
  [31:0] CAP{i}_VALUE — Value of last capture on channel {i}
0x108 CAP_STATUS ro — Edge of last capture trigger
  [2] CAP2_EDGE — Edge of last capture trigger on channel 2, 0: posedge, 1: negedge
  [1] CAP1_EDGE — Edge of last capture trigger on channel 1, 0: posedge, 1: negedge
  [0] CAP0_EDGE — Edge of last capture trigger on channel 0, 0: posedge, 1: negedge
0x10C UPDATE_CFG reset 0x55 — Enable update.
  [7] OP2_FORCE_UP — a toggle (software invert its value) will trigger a forced update of active registers in PWM operator 2
  [6] OP2_UP_EN — When set and PWM_GLOBAL_UP_EN is set, update of active registers in PWM operator 2 are enabled
  [5] OP1_FORCE_UP — a toggle (software invert its value) will trigger a forced update of active registers in PWM operator 1
  [4] OP1_UP_EN — When set and PWM_GLOBAL_UP_EN is set, update of active registers in PWM operator 1 are enabled
  [3] OP0_FORCE_UP — a toggle (software invert its value) will trigger a forced update of active registers in PWM operator 0
  [2] OP0_UP_EN — When set and PWM_GLOBAL_UP_EN is set, update of active registers in PWM operator 0 are enabled
  [1] GLOBAL_FORCE_UP — a toggle (software invert its value) will trigger a forced update of all active registers in MCPWM module
  [0] GLOBAL_UP_EN — The global enable of update of all active registers in MCPWM module
0x110 INT_ENA — Interrupt enable bits
  [29] CAP2_INT_ENA — The enable bit for the interrupt triggered by capture on channel 2.
  [28] CAP1_INT_ENA — The enable bit for the interrupt triggered by capture on channel 1.
  [27] CAP0_INT_ENA — The enable bit for the interrupt triggered by capture on channel 0.
  [26] TZ2_OST_INT_ENA — The enable bit for the interrupt triggered by a one-shot mode action on PWM2.
  [25] TZ1_OST_INT_ENA — The enable bit for the interrupt triggered by a one-shot mode action on PWM1.
  [24] TZ0_OST_INT_ENA — The enable bit for the interrupt triggered by a one-shot mode action on PWM0.
  [23] TZ2_CBC_INT_ENA — The enable bit for the interrupt triggered by a cycle-by-cycle mode action on PWM2.
  [22] TZ1_CBC_INT_ENA — The enable bit for the interrupt triggered by a cycle-by-cycle mode action on PWM1.
  [21] TZ0_CBC_INT_ENA — The enable bit for the interrupt triggered by a cycle-by-cycle mode action on PWM0.
  [20] CMPR2_TEB_INT_ENA — The enable bit for the interrupt triggered by a PWM operator 2 TEB event
  [19] CMPR1_TEB_INT_ENA — The enable bit for the interrupt triggered by a PWM operator 1 TEB event
  [18] CMPR0_TEB_INT_ENA — The enable bit for the interrupt triggered by a PWM operator 0 TEB event
  [17] CMPR2_TEA_INT_ENA — The enable bit for the interrupt triggered by a PWM operator 2 TEA event
  [16] CMPR1_TEA_INT_ENA — The enable bit for the interrupt triggered by a PWM operator 1 TEA event
  [15] CMPR0_TEA_INT_ENA — The enable bit for the interrupt triggered by a PWM operator 0 TEA event
  [14] FAULT2_CLR_INT_ENA — The enable bit for the interrupt triggered when event_f2 ends.
  [13] FAULT1_CLR_INT_ENA — The enable bit for the interrupt triggered when event_f1 ends.
  [12] FAULT0_CLR_INT_ENA — The enable bit for the interrupt triggered when event_f0 ends.
  [11] FAULT2_INT_ENA — The enable bit for the interrupt triggered when event_f2 starts.
  [10] FAULT1_INT_ENA — The enable bit for the interrupt triggered when event_f1 starts.
  [9] FAULT0_INT_ENA — The enable bit for the interrupt triggered when event_f0 starts.
  [8] TIMER2_TEP_INT_ENA — The enable bit for the interrupt triggered by a PWM timer 2 TEP event.
  [7] TIMER1_TEP_INT_ENA — The enable bit for the interrupt triggered by a PWM timer 1 TEP event.
  [6] TIMER0_TEP_INT_ENA — The enable bit for the interrupt triggered by a PWM timer 0 TEP event.
  [5] TIMER2_TEZ_INT_ENA — The enable bit for the interrupt triggered by a PWM timer 2 TEZ event.
  [4] TIMER1_TEZ_INT_ENA — The enable bit for the interrupt triggered by a PWM timer 1 TEZ event.
  [3] TIMER0_TEZ_INT_ENA — The enable bit for the interrupt triggered by a PWM timer 0 TEZ event.
  [2] TIMER2_STOP_INT_ENA — The enable bit for the interrupt triggered when the timer 2 stops.
  [1] TIMER1_STOP_INT_ENA — The enable bit for the interrupt triggered when the timer 1 stops.
  [0] TIMER0_STOP_INT_ENA — The enable bit for the interrupt triggered when the timer 0 stops.
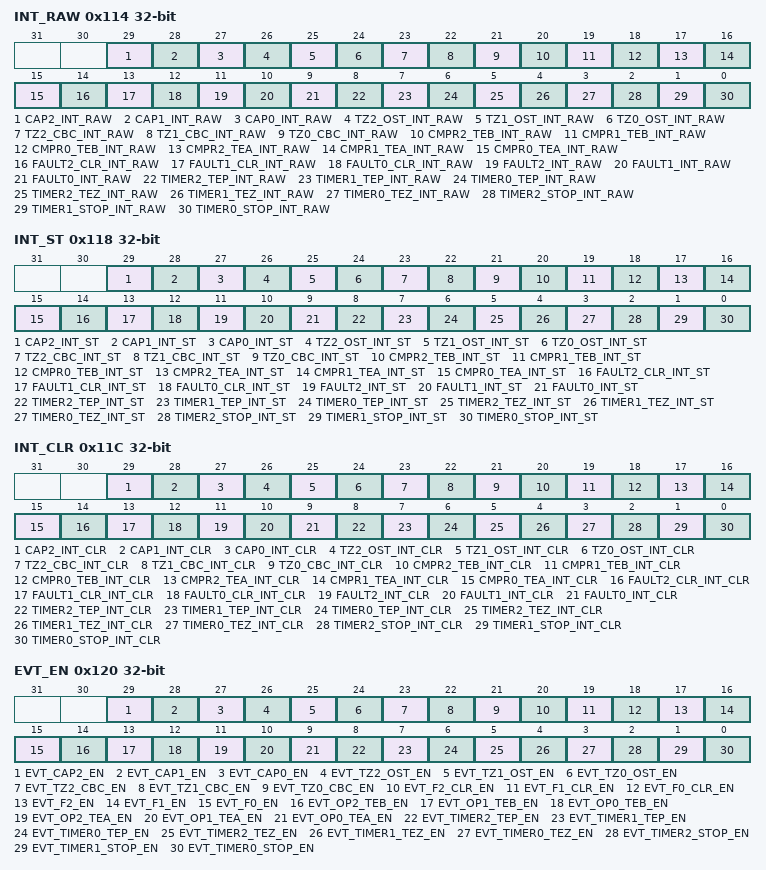
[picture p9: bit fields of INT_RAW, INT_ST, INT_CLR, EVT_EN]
0x114 INT_RAW — Raw interrupt status
  [29] CAP2_INT_RAW — The raw status bit for the interrupt triggered by capture on channel 2.
  [28] CAP1_INT_RAW — The raw status bit for the interrupt triggered by capture on channel 1.
  [27] CAP0_INT_RAW — The raw status bit for the interrupt triggered by capture on channel 0.
  [26] TZ2_OST_INT_RAW — The raw status bit for the interrupt triggered by a one-shot mode action on PWM2.
  [25] TZ1_OST_INT_RAW — The raw status bit for the interrupt triggered by a one-shot mode action on PWM1.
  [24] TZ0_OST_INT_RAW — The raw status bit for the interrupt triggered by a one-shot mode action on PWM0.
  [23] TZ2_CBC_INT_RAW — The raw status bit for the interrupt triggered by a cycle-by-cycle mode action on PWM2.
  [22] TZ1_CBC_INT_RAW — The raw status bit for the interrupt triggered by a cycle-by-cycle mode action on PWM1.
  [21] TZ0_CBC_INT_RAW — The raw status bit for the interrupt triggered by a cycle-by-cycle mode action on PWM0.
  [20] CMPR2_TEB_INT_RAW — The raw status bit for the interrupt triggered by a PWM operator 2 TEB event
  [19] CMPR1_TEB_INT_RAW — The raw status bit for the interrupt triggered by a PWM operator 1 TEB event
  [18] CMPR0_TEB_INT_RAW — The raw status bit for the interrupt triggered by a PWM operator 0 TEB event
  [17] CMPR2_TEA_INT_RAW — The raw status bit for the interrupt triggered by a PWM operator 2 TEA event
  [16] CMPR1_TEA_INT_RAW — The raw status bit for the interrupt triggered by a PWM operator 1 TEA event
  [15] CMPR0_TEA_INT_RAW — The raw status bit for the interrupt triggered by a PWM operator 0 TEA event
  [14] FAULT2_CLR_INT_RAW — The raw status bit for the interrupt triggered when event_f2 ends.
  [13] FAULT1_CLR_INT_RAW — The raw status bit for the interrupt triggered when event_f1 ends.
  [12] FAULT0_CLR_INT_RAW — The raw status bit for the interrupt triggered when event_f0 ends.
  [11] FAULT2_INT_RAW — The raw status bit for the interrupt triggered when event_f2 starts.
  [10] FAULT1_INT_RAW — The raw status bit for the interrupt triggered when event_f1 starts.
  [9] FAULT0_INT_RAW — The raw status bit for the interrupt triggered when event_f0 starts.
  [8] TIMER2_TEP_INT_RAW — The raw status bit for the interrupt triggered by a PWM timer 2 TEP event.
  [7] TIMER1_TEP_INT_RAW — The raw status bit for the interrupt triggered by a PWM timer 1 TEP event.
  [6] TIMER0_TEP_INT_RAW — The raw status bit for the interrupt triggered by a PWM timer 0 TEP event.
  [5] TIMER2_TEZ_INT_RAW — The raw status bit for the interrupt triggered by a PWM timer 2 TEZ event.
  [4] TIMER1_TEZ_INT_RAW — The raw status bit for the interrupt triggered by a PWM timer 1 TEZ event.
  [3] TIMER0_TEZ_INT_RAW — The raw status bit for the interrupt triggered by a PWM timer 0 TEZ event.
  [2] TIMER2_STOP_INT_RAW — The raw status bit for the interrupt triggered when the timer 2 stops.
  [1] TIMER1_STOP_INT_RAW — The raw status bit for the interrupt triggered when the timer 1 stops.
  [0] TIMER0_STOP_INT_RAW — The raw status bit for the interrupt triggered when the timer 0 stops.
0x118 INT_ST ro — Masked interrupt status
  [29] CAP2_INT_ST — The masked status bit for the interrupt triggered by capture on channel 2.
  [28] CAP1_INT_ST — The masked status bit for the interrupt triggered by capture on channel 1.
  [27] CAP0_INT_ST — The masked status bit for the interrupt triggered by capture on channel 0.
  [26] TZ2_OST_INT_ST — The masked status bit for the interrupt triggered by a one-shot mode action on PWM2.
  [25] TZ1_OST_INT_ST — The masked status bit for the interrupt triggered by a one-shot mode action on PWM1.
  [24] TZ0_OST_INT_ST — The masked status bit for the interrupt triggered by a one-shot mode action on PWM0.
  [23] TZ2_CBC_INT_ST — The masked status bit for the interrupt triggered by a cycle-by-cycle mode action on PWM2.
  [22] TZ1_CBC_INT_ST — The masked status bit for the interrupt triggered by a cycle-by-cycle mode action on PWM1.
  [21] TZ0_CBC_INT_ST — The masked status bit for the interrupt triggered by a cycle-by-cycle mode action on PWM0.
  [20] CMPR2_TEB_INT_ST — The masked status bit for the interrupt triggered by a PWM operator 2 TEB event
  [19] CMPR1_TEB_INT_ST — The masked status bit for the interrupt triggered by a PWM operator 1 TEB event
  [18] CMPR0_TEB_INT_ST — The masked status bit for the interrupt triggered by a PWM operator 0 TEB event
  [17] CMPR2_TEA_INT_ST — The masked status bit for the interrupt triggered by a PWM operator 2 TEA event
  [16] CMPR1_TEA_INT_ST — The masked status bit for the interrupt triggered by a PWM operator 1 TEA event
  [15] CMPR0_TEA_INT_ST — The masked status bit for the interrupt triggered by a PWM operator 0 TEA event
  [14] FAULT2_CLR_INT_ST — The masked status bit for the interrupt triggered when event_f2 ends.
  [13] FAULT1_CLR_INT_ST — The masked status bit for the interrupt triggered when event_f1 ends.
  [12] FAULT0_CLR_INT_ST — The masked status bit for the interrupt triggered when event_f0 ends.
  [11] FAULT2_INT_ST — The masked status bit for the interrupt triggered when event_f2 starts.
  [10] FAULT1_INT_ST — The masked status bit for the interrupt triggered when event_f1 starts.
  [9] FAULT0_INT_ST — The masked status bit for the interrupt triggered when event_f0 starts.
  [8] TIMER2_TEP_INT_ST — The masked status bit for the interrupt triggered by a PWM timer 2 TEP event.
  [7] TIMER1_TEP_INT_ST — The masked status bit for the interrupt triggered by a PWM timer 1 TEP event.
  [6] TIMER0_TEP_INT_ST — The masked status bit for the interrupt triggered by a PWM timer 0 TEP event.
  [5] TIMER2_TEZ_INT_ST — The masked status bit for the interrupt triggered by a PWM timer 2 TEZ event.
  [4] TIMER1_TEZ_INT_ST — The masked status bit for the interrupt triggered by a PWM timer 1 TEZ event.
  [3] TIMER0_TEZ_INT_ST — The masked status bit for the interrupt triggered by a PWM timer 0 TEZ event.
  [2] TIMER2_STOP_INT_ST — The masked status bit for the interrupt triggered when the timer 2 stops.
  [1] TIMER1_STOP_INT_ST — The masked status bit for the interrupt triggered when the timer 1 stops.
  [0] TIMER0_STOP_INT_ST — The masked status bit for the interrupt triggered when the timer 0 stops.
0x11C INT_CLR wo — Interrupt clear bits
  [29] CAP2_INT_CLR — Set this bit to clear the interrupt triggered by capture on channel 2.
  [28] CAP1_INT_CLR — Set this bit to clear the interrupt triggered by capture on channel 1.
  [27] CAP0_INT_CLR — Set this bit to clear the interrupt triggered by capture on channel 0.
  [26] TZ2_OST_INT_CLR — Set this bit to clear the interrupt triggered by a one-shot mode action on PWM2.
  [25] TZ1_OST_INT_CLR — Set this bit to clear the interrupt triggered by a one-shot mode action on PWM1.
  [24] TZ0_OST_INT_CLR — Set this bit to clear the interrupt triggered by a one-shot mode action on PWM0.
  [23] TZ2_CBC_INT_CLR — Set this bit to clear the interrupt triggered by a cycle-by-cycle mode action on PWM2.
  [22] TZ1_CBC_INT_CLR — Set this bit to clear the interrupt triggered by a cycle-by-cycle mode action on PWM1.
  [21] TZ0_CBC_INT_CLR — Set this bit to clear the interrupt triggered by a cycle-by-cycle mode action on PWM0.
  [20] CMPR2_TEB_INT_CLR — Set this bit to clear the interrupt triggered by a PWM operator 2 TEB event
  [19] CMPR1_TEB_INT_CLR — Set this bit to clear the interrupt triggered by a PWM operator 1 TEB event
  [18] CMPR0_TEB_INT_CLR — Set this bit to clear the interrupt triggered by a PWM operator 0 TEB event
  [17] CMPR2_TEA_INT_CLR — Set this bit to clear the interrupt triggered by a PWM operator 2 TEA event
  [16] CMPR1_TEA_INT_CLR — Set this bit to clear the interrupt triggered by a PWM operator 1 TEA event
  [15] CMPR0_TEA_INT_CLR — Set this bit to clear the interrupt triggered by a PWM operator 0 TEA event
  [14] FAULT2_CLR_INT_CLR — Set this bit to clear the interrupt triggered when event_f2 ends.
  [13] FAULT1_CLR_INT_CLR — Set this bit to clear the interrupt triggered when event_f1 ends.
  [12] FAULT0_CLR_INT_CLR — Set this bit to clear the interrupt triggered when event_f0 ends.
  [11] FAULT2_INT_CLR — Set this bit to clear the interrupt triggered when event_f2 starts.
  [10] FAULT1_INT_CLR — Set this bit to clear the interrupt triggered when event_f1 starts.
  [9] FAULT0_INT_CLR — Set this bit to clear the interrupt triggered when event_f0 starts.
  [8] TIMER2_TEP_INT_CLR — Set this bit to clear the interrupt triggered by a PWM timer 2 TEP event.
  [7] TIMER1_TEP_INT_CLR — Set this bit to clear the interrupt triggered by a PWM timer 1 TEP event.
  [6] TIMER0_TEP_INT_CLR — Set this bit to clear the interrupt triggered by a PWM timer 0 TEP event.
  [5] TIMER2_TEZ_INT_CLR — Set this bit to clear the interrupt triggered by a PWM timer 2 TEZ event.
  [4] TIMER1_TEZ_INT_CLR — Set this bit to clear the interrupt triggered by a PWM timer 1 TEZ event.
  [3] TIMER0_TEZ_INT_CLR — Set this bit to clear the interrupt triggered by a PWM timer 0 TEZ event.
  [2] TIMER2_STOP_INT_CLR — Set this bit to clear the interrupt triggered when the timer 2 stops.
  [1] TIMER1_STOP_INT_CLR — Set this bit to clear the interrupt triggered when the timer 1 stops.
  [0] TIMER0_STOP_INT_CLR — Set this bit to clear the interrupt triggered when the timer 0 stops.
0x120 EVT_EN — MCPWM event enable register
  [29] EVT_CAP2_EN — set this bit high to enable capture2 event generate
  [28] EVT_CAP1_EN — set this bit high to enable capture1 event generate
  [27] EVT_CAP0_EN — set this bit high to enable capture0 event generate
  [26] EVT_TZ2_OST_EN — set this bit high to enable one shot trip2 event generate
  [25] EVT_TZ1_OST_EN — set this bit high to enable one shot trip1 event generate
  [24] EVT_TZ0_OST_EN — set this bit high to enable one shot trip0 event generate
  [23] EVT_TZ2_CBC_EN — set this bit high to enable cycle by cycle trip2 event generate
  [22] EVT_TZ1_CBC_EN — set this bit high to enable cycle by cycle trip1 event generate
  [21] EVT_TZ0_CBC_EN — set this bit high to enable cycle by cycle trip0 event generate
  [20] EVT_F2_CLR_EN — set this bit high to enable fault2 clear event generate
  [19] EVT_F1_CLR_EN — set this bit high to enable fault1 clear event generate
  [18] EVT_F0_CLR_EN — set this bit high to enable fault0 clear event generate
  [17] EVT_F2_EN — set this bit high to enable fault2 event generate
  [16] EVT_F1_EN — set this bit high to enable fault1 event generate
  [15] EVT_F0_EN — set this bit high to enable fault0 event generate
  [14] EVT_OP2_TEB_EN — set this bit high to enable PWM generator2 timer equal b event generate
  [13] EVT_OP1_TEB_EN — set this bit high to enable PWM generator1 timer equal b event generate
  [12] EVT_OP0_TEB_EN — set this bit high to enable PWM generator0 timer equal b event generate
  [11] EVT_OP2_TEA_EN — set this bit high to enable PWM generator2 timer equal a event generate
  [10] EVT_OP1_TEA_EN — set this bit high to enable PWM generator1 timer equal a event generate
  [9] EVT_OP0_TEA_EN — set this bit high to enable PWM generator0 timer equal a event generate
  [8] EVT_TIMER2_TEP_EN — set this bit high to enable timer2 equal period event generate
  [7] EVT_TIMER1_TEP_EN — set this bit high to enable timer1 equal period event generate
  [6] EVT_TIMER0_TEP_EN — set this bit high to enable timer0 equal period event generate
  [5] EVT_TIMER2_TEZ_EN — set this bit high to enable timer2 equal zero event generate
  [4] EVT_TIMER1_TEZ_EN — set this bit high to enable timer1 equal zero event generate
  [3] EVT_TIMER0_TEZ_EN — set this bit high to enable timer0 equal zero event generate
  [2] EVT_TIMER2_STOP_EN — set this bit high to enable timer2 stop event generate
  [1] EVT_TIMER1_STOP_EN — set this bit high to enable timer1 stop event generate
  [0] EVT_TIMER0_STOP_EN — set this bit high to enable timer0 stop event generate
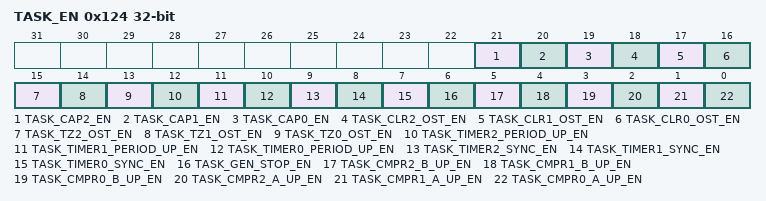
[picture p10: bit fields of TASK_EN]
0x124 TASK_EN — MCPWM task enable register
  [21] TASK_CAP2_EN — set this bit high to enable capture2 task receive
  [20] TASK_CAP1_EN — set this bit high to enable capture1 task receive
  [19] TASK_CAP0_EN — set this bit high to enable capture0 task receive
  [18] TASK_CLR2_OST_EN — set this bit high to enable one shot trip2 clear task receive
  [17] TASK_CLR1_OST_EN — set this bit high to enable one shot trip1 clear task receive
  [16] TASK_CLR0_OST_EN — set this bit high to enable one shot trip0 clear task receive
  [15] TASK_TZ2_OST_EN — set this bit high to enable one shot trip2 task receive
  [14] TASK_TZ1_OST_EN — set this bit high to enable one shot trip1 task receive
  [13] TASK_TZ0_OST_EN — set this bit high to enable one shot trip0 task receive
  [12] TASK_TIMER2_PERIOD_UP_EN — set this bit high to enable timer2 period update task receive
  [11] TASK_TIMER1_PERIOD_UP_EN — set this bit high to enable timer1 period update task receive
  [10] TASK_TIMER0_PERIOD_UP_EN — set this bit high to enable timer0 period update task receive
  [9] TASK_TIMER2_SYNC_EN — set this bit high to enable timer2 sync task receive
  [8] TASK_TIMER1_SYNC_EN — set this bit high to enable timer1 sync task receive
  [7] TASK_TIMER0_SYNC_EN — set this bit high to enable timer0 sync task receive
  [6] TASK_GEN_STOP_EN — set this bit high to enable all PWM generate stop task receive
  [5] TASK_CMPR2_B_UP_EN — set this bit high to enable PWM generator2 timer stamp B's shadow register update task receive
  [4] TASK_CMPR1_B_UP_EN — set this bit high to enable PWM generator1 timer stamp B's shadow register update task receive
  [3] TASK_CMPR0_B_UP_EN — set this bit high to enable PWM generator0 timer stamp B's shadow register update task receive
  [2] TASK_CMPR2_A_UP_EN — set this bit high to enable PWM generator2 timer stamp A's shadow register update task receive
  [1] TASK_CMPR1_A_UP_EN — set this bit high to enable PWM generator1 timer stamp A's shadow register update task receive
  [0] TASK_CMPR0_A_UP_EN — set this bit high to enable PWM generator0 timer stamp A's shadow register update task receive
0x128 CLK — MCPWM APB configuration register
  [0] EN — Force clock on for this register file
0x12C VERSION reset 0x2201240
  [27:0] DATE — Version of this register file
